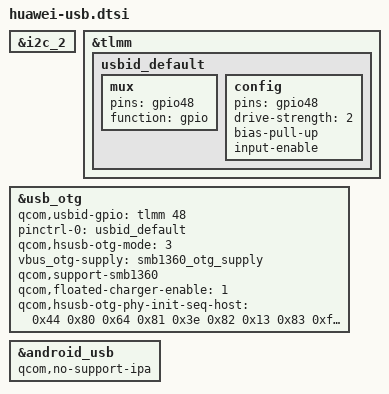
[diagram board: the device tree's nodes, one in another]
/*remove type-c support*/
&i2c_2 {
	/delete-node/ pericom-type-c@1d;
};

&tlmm {
	usbid_default: usbid_default {
		mux {
			pins = "gpio48";
			function = "gpio";
		};
		config {
			pins = "gpio48";
			drive-strength = <2>;   /* 2 MA */
			bias-pull-up;           /* PULL UP*/
			input-enable;
		};
	};
};

&usb_otg{
	qcom,usbid-gpio = <&tlmm 48 0x00>;
	pinctrl-names = "default";
	pinctrl-0 = <&usbid_default>;
	qcom,hsusb-otg-mode = <3>;	/* enable otg mode */
	vbus_otg-supply = <&smb1360_otg_supply>;
	qcom,support-smb1360;
	qcom,floated-charger-enable = <1>;
	qcom,hsusb-otg-phy-init-seq-host = <0x44 0x80 0x64 0x81 0x3e 0x82 0x13 0x83 0xffffffff>;
};

&android_usb {
	/*8917 does not support ipa ports*/
	qcom,no-support-ipa;
};
